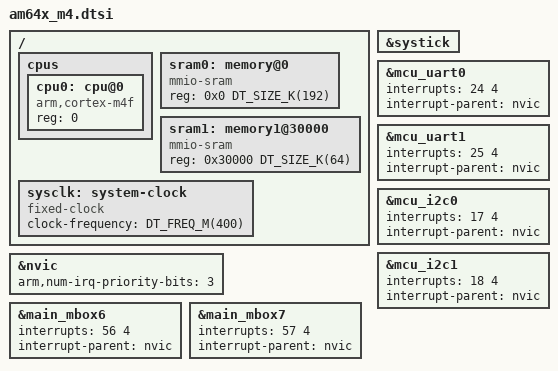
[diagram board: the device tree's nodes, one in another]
/*
 * Copyright (c) 2024 PHYTEC Messtechnik GmbH
 * Copyright (c) 2025 Texas Instruments Incorporated
 *
 * SPDX-License-Identifier: Apache-2.0
 */

#include <mem.h>
#include <freq.h>
#include <arm/armv7-m.dtsi>
#include <ti/am64x_main.dtsi>
#include <ti/am64x_mcu.dtsi>

/ {
	cpus {
		#address-cells = <1>;
		#size-cells = <0>;

		cpu0: cpu@0 {
			device_type = "cpu";
			compatible = "arm,cortex-m4f";
			reg = <0>;
		};
	};

	sram0: memory@0 {
		compatible = "mmio-sram";
		reg = <0x0 DT_SIZE_K(192)>;		/* 192 KB of SRAM (I-Code) */
	};

	sram1: memory1@30000 {
		compatible = "mmio-sram";
		reg = <0x30000 DT_SIZE_K(64)>;		/* 64 KB of SRAM (D-Code) */
	};

	sysclk: system-clock {
		compatible = "fixed-clock";
		clock-frequency = <DT_FREQ_M(400)>;
		#clock-cells = <0>;
	};
};

&nvic {
	arm,num-irq-priority-bits = <3>;
};

&systick {
	status = "okay";
};

&mcu_uart0 {
	interrupts = <24 4>;
	interrupt-parent = <&nvic>;
};

&mcu_uart1 {
	interrupts = <25 4>;
	interrupt-parent = <&nvic>;
};

&mcu_i2c0 {
	interrupts = <17 4>;
	interrupt-parent = <&nvic>;
};

&mcu_i2c1 {
	interrupts = <18 4>;
	interrupt-parent = <&nvic>;
};

&main_mbox6 {
	interrupts = <56 4>;
	interrupt-parent = <&nvic>;
};

&main_mbox7 {
	interrupts = <57 4>;
	interrupt-parent = <&nvic>;
};
